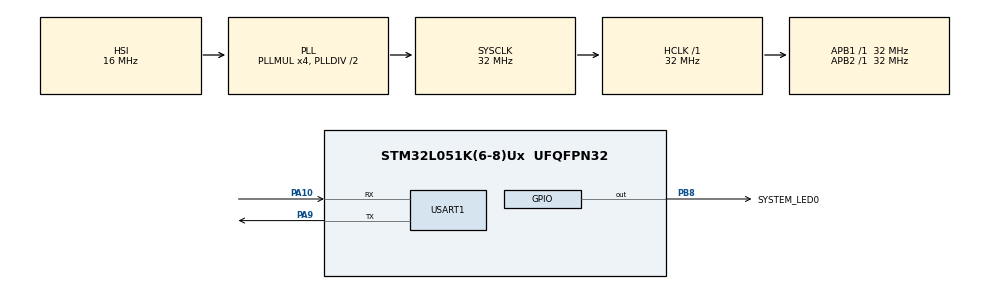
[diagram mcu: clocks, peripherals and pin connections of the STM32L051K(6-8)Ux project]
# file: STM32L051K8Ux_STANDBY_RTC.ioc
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Dma.Request0=USART1_RX
Dma.Request1=USART1_TX
Dma.USART1_RX.0.Direction=DMA_PERIPH_TO_MEMORY
Dma.USART1_RX.0.Instance=DMA1_Channel3
Dma.USART1_RX.0.MemDataAlignment=DMA_MDATAALIGN_BYTE
Dma.USART1_RX.0.MemInc=DMA_MINC_ENABLE
Dma.USART1_RX.0.Mode=DMA_NORMAL
Dma.USART1_RX.0.PeriphDataAlignment=DMA_PDATAALIGN_BYTE
Dma.USART1_RX.0.PeriphInc=DMA_PINC_DISABLE
Dma.USART1_RX.0.Priority=DMA_PRIORITY_LOW
Dma.USART1_TX.1.Direction=DMA_MEMORY_TO_PERIPH
Dma.USART1_TX.1.Instance=DMA1_Channel2
Dma.USART1_TX.1.MemDataAlignment=DMA_MDATAALIGN_BYTE
Dma.USART1_TX.1.MemInc=DMA_MINC_ENABLE
Dma.USART1_TX.1.Mode=DMA_NORMAL
Dma.USART1_TX.1.PeriphDataAlignment=DMA_PDATAALIGN_BYTE
Dma.USART1_TX.1.PeriphInc=DMA_PINC_DISABLE
Dma.USART1_TX.1.Priority=DMA_PRIORITY_LOW
Mcu.Family=STM32L0
Mcu.Name=STM32L051K(6-8)Ux
Mcu.Package=UFQFPN32
NVIC.DMA1_Channel2_3_IRQn=true\:0\:0\:false\:false\:true\:false\:true
NVIC.USART1_IRQn=true\:0\:0\:false\:false\:true\:true\:true
PA0.Mode=SYS_WakeUp0
PA0.Signal=SYS_WKUP1
PA10.Mode=Asynchronous
PA10.Signal=USART1_RX
PA13.Mode=Serial_Wire
PA13.Signal=SYS_SWDIO
PA14.Mode=Serial_Wire
PA14.Signal=SYS_SWCLK
PA9.Mode=Asynchronous
PA9.Signal=USART1_TX
PB8.GPIO_Label=SYSTEM_LED0
PB8.Signal=GPIO_Output
PC14-OSC32_IN.Mode=LSE-External-Oscillator
PC14-OSC32_IN.Signal=RCC_OSC32_IN
PC15-OSC32_OUT.Mode=LSE-External-Oscillator
PC15-OSC32_OUT.Signal=RCC_OSC32_OUT
ProjectManager.HeapSize=0x200
ProjectManager.StackSize=0x400
ProjectManager.TargetToolchain=MDK-ARM V5.27
RCC.AHBFreq_Value=32000000
RCC.APB1Freq_Value=32000000
RCC.APB1TimFreq_Value=32000000
RCC.APB2Freq_Value=32000000
RCC.APB2TimFreq_Value=32000000
RCC.HCLKFreq_Value=32000000
RCC.HSI16_VALUE=16000000
RCC.HSI_VALUE=16000000
RCC.MSI_VALUE=2097000
RCC.PLLMUL=RCC_PLLMUL_4
RCC.SYSCLKFreq_VALUE=32000000
RCC.SYSCLKSource=RCC_SYSCLKSOURCE_PLLCLK
RCC.VCOOutputFreq_Value=64000000
USART1.VirtualMode-Asynchronous=VM_ASYNC
board=custom

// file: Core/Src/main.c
/* USER CODE BEGIN Header */
/**
  ******************************************************************************
  * @file           : main.c
  * @brief          : Main program body
  ******************************************************************************
  * @attention
  *
  * <h2><center>&copy; Copyright (c) 2021 STMicroelectronics.
  * All rights reserved.</center></h2>
  *
  * This software component is licensed by ST under BSD 3-Clause license,
  * the "License"; You may not use this file except in compliance with the
  * License. You may obtain a copy of the License at:
  *                        opensource.org/licenses/BSD-3-Clause
  *
  ******************************************************************************
  */
/* USER CODE END Header */
#include "main.h"
#include "dma.h"
#include "usart.h"
#include "gpio.h"

/* USER CODE BEGIN Includes */

#include "string.h"
/* USER CODE END Includes */

void SystemClock_Config(void);

int main(void)
{

  /* MCU Configuration--------------------------------------------------------*/

  /* Reset of all peripherals, Initializes the Flash interface and the Systick. */
  HAL_Init();

  /* Configure the system clock */
  SystemClock_Config();

  /* Initialize all configured peripherals */
  MX_GPIO_Init();
  MX_DMA_Init();
  MX_USART1_UART_Init();
  /* USER CODE BEGIN 2 */

    if(__HAL_PWR_GET_FLAG(PWR_FLAG_SB) != RESET)
    {
        __HAL_PWR_CLEAR_FLAG(PWR_FLAG_SB);  // Clear the flag
        /* Display the string */
        char *str = "Wakeup from the STANDBY mode\n\n";
        HAL_UART_Transmit(&huart1, (uint8_t *)str, strlen(str), HAL_MAX_DELAY);

        /* Blink the led*/
        for (int i = 0; i < 20; i++)
        {
            HAL_GPIO_TogglePin(SYSTEM_LED0_GPIO_Port, SYSTEM_LED0_Pin);
            HAL_Delay(200);
        }

        HAL_PWR_DisableWakeUpPin(PWR_WAKEUP_PIN1);
    }

    /* Clear the wu Flag */
    __HAL_PWR_CLEAR_FLAG(PWR_FLAG_WU);
    char *str = "About to enter the STANDBY mode\r\n";
    HAL_UART_Transmit(&huart1, (uint8_t *)str, strlen(str), HAL_MAX_DELAY);

    for (int i = 0; i < 20; i++)
    {
        HAL_GPIO_TogglePin(SYSTEM_LED0_GPIO_Port, SYSTEM_LED0_Pin);
        HAL_Delay(750);
    }

    /* Enable the WAKEUP PIN */
    HAL_PWR_EnableWakeUpPin(PWR_WAKEUP_PIN1);

    char *str2 = "STANDBY MODE is on\r\n";
    HAL_UART_Transmit(&huart1, (uint8_t *)str2, strlen(str2), HAL_MAX_DELAY);
    HAL_PWREx_EnableUltraLowPower();

    /* Finally enter the standby mode */
    HAL_PWR_EnterSTANDBYMode();
  /* USER CODE END 2 */

  /* Infinite loop */
  while (1)
  {

  }
}

void SystemClock_Config(void)
{
  RCC_OscInitTypeDef RCC_OscInitStruct = {0};
  RCC_ClkInitTypeDef RCC_ClkInitStruct = {0};
  RCC_PeriphCLKInitTypeDef PeriphClkInit = {0};

  /** Configure the main internal regulator output voltage
  */
  __HAL_PWR_VOLTAGESCALING_CONFIG(PWR_REGULATOR_VOLTAGE_SCALE1);
  /** Initializes the RCC Oscillators according to the specified parameters
  * in the RCC_OscInitTypeDef structure.
  */
  RCC_OscInitStruct.OscillatorType = RCC_OSCILLATORTYPE_HSI;
  RCC_OscInitStruct.HSIState = RCC_HSI_ON;
  RCC_OscInitStruct.HSICalibrationValue = RCC_HSICALIBRATION_DEFAULT;
  RCC_OscInitStruct.PLL.PLLState = RCC_PLL_ON;
  RCC_OscInitStruct.PLL.PLLSource = RCC_PLLSOURCE_HSI;
  RCC_OscInitStruct.PLL.PLLMUL = RCC_PLLMUL_4;
  RCC_OscInitStruct.PLL.PLLDIV = RCC_PLLDIV_2;
  if (HAL_RCC_OscConfig(&RCC_OscInitStruct) != HAL_OK)
  {
    Error_Handler();
  }
  /** Initializes the CPU, AHB and APB buses clocks
  */
  RCC_ClkInitStruct.ClockType = RCC_CLOCKTYPE_HCLK|RCC_CLOCKTYPE_SYSCLK
                              |RCC_CLOCKTYPE_PCLK1|RCC_CLOCKTYPE_PCLK2;
  RCC_ClkInitStruct.SYSCLKSource = RCC_SYSCLKSOURCE_PLLCLK;
  RCC_ClkInitStruct.AHBCLKDivider = RCC_SYSCLK_DIV1;
  RCC_ClkInitStruct.APB1CLKDivider = RCC_HCLK_DIV1;
  RCC_ClkInitStruct.APB2CLKDivider = RCC_HCLK_DIV1;

  if (HAL_RCC_ClockConfig(&RCC_ClkInitStruct, FLASH_LATENCY_1) != HAL_OK)
  {
    Error_Handler();
  }
  PeriphClkInit.PeriphClockSelection = RCC_PERIPHCLK_USART1;
  PeriphClkInit.Usart1ClockSelection = RCC_USART1CLKSOURCE_PCLK2;
  if (HAL_RCCEx_PeriphCLKConfig(&PeriphClkInit) != HAL_OK)
  {
    Error_Handler();
  }
}

void Error_Handler(void)
{
}

/************************ (C) COPYRIGHT STMicroelectronics *****END OF FILE****/
